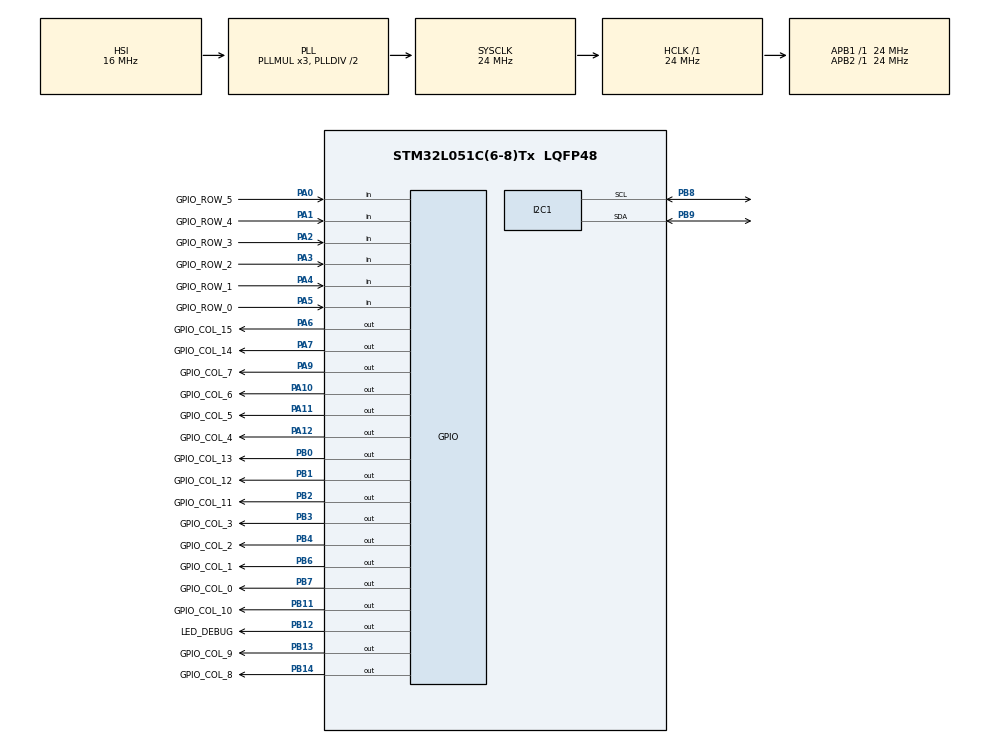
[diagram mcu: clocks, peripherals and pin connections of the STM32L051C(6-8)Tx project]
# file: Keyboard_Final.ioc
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I2C1.Timing=0x00506682
Mcu.Family=STM32L0
Mcu.Name=STM32L051C(6-8)Tx
Mcu.Package=LQFP48
PA0.GPIO_Label=GPIO_ROW_5
PA0.Signal=GPIO_Input
PA1.GPIO_Label=GPIO_ROW_4
PA1.Signal=GPIO_Input
PA10.GPIO_Label=GPIO_COL_6
PA10.Signal=GPIO_Output
PA11.GPIO_Label=GPIO_COL_5
PA11.Signal=GPIO_Output
PA12.GPIO_Label=GPIO_COL_4
PA12.Signal=GPIO_Output
PA13.Mode=Serial_Wire
PA13.Signal=SYS_SWDIO
PA14.Mode=Serial_Wire
PA14.Signal=SYS_SWCLK
PA2.GPIO_Label=GPIO_ROW_3
PA2.Signal=GPIO_Input
PA3.GPIO_Label=GPIO_ROW_2
PA3.Signal=GPIO_Input
PA4.GPIO_Label=GPIO_ROW_1
PA4.Signal=GPIO_Input
PA5.GPIO_Label=GPIO_ROW_0
PA5.Signal=GPIO_Input
PA6.GPIO_Label=GPIO_COL_15
PA6.Signal=GPIO_Output
PA7.GPIO_Label=GPIO_COL_14
PA7.Signal=GPIO_Output
PA9.GPIO_Label=GPIO_COL_7
PA9.Signal=GPIO_Output
PB0.GPIO_Label=GPIO_COL_13
PB0.Signal=GPIO_Output
PB1.GPIO_Label=GPIO_COL_12
PB1.Signal=GPIO_Output
PB11.GPIO_Label=GPIO_COL_10
PB11.Signal=GPIO_Output
PB12.GPIO_Label=LED_DEBUG
PB12.Signal=GPIO_Output
PB13.GPIO_Label=GPIO_COL_9
PB13.Signal=GPIO_Output
PB14.GPIO_Label=GPIO_COL_8
PB14.Signal=GPIO_Output
PB2.GPIO_Label=GPIO_COL_11
PB2.Signal=GPIO_Output
PB3.GPIO_Label=GPIO_COL_3
PB3.Signal=GPIO_Output
PB4.GPIO_Label=GPIO_COL_2
PB4.Signal=GPIO_Output
PB6.GPIO_Label=GPIO_COL_1
PB6.Signal=GPIO_Output
PB7.GPIO_Label=GPIO_COL_0
PB7.Signal=GPIO_Output
PB8.Mode=I2C
PB8.Signal=I2C1_SCL
PB9.Mode=I2C
PB9.Signal=I2C1_SDA
ProjectManager.HeapSize=0x200
ProjectManager.StackSize=0x400
ProjectManager.TargetToolchain=SW4STM32
RCC.AHBFreq_Value=24000000
RCC.APB1Freq_Value=24000000
RCC.APB1TimFreq_Value=24000000
RCC.APB2Freq_Value=24000000
RCC.APB2TimFreq_Value=24000000
RCC.HCLKFreq_Value=24000000
RCC.HSE_VALUE=8000000
RCC.HSI16_VALUE=16000000
RCC.HSI_VALUE=16000000
RCC.LSE_VALUE=32768
RCC.MSI_VALUE=2097000
RCC.SYSCLKFreq_VALUE=24000000
RCC.SYSCLKSource=RCC_SYSCLKSOURCE_PLLCLK
RCC.VCOOutputFreq_Value=48000000
board=custom

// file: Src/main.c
/* USER CODE BEGIN Header */
/**
  ******************************************************************************
  * @file           : main.c
  * @brief          : Main program body
  ******************************************************************************
  * @attention
  *
  * <h2><center>&copy; Copyright (c) 2019 STMicroelectronics.
  * All rights reserved.</center></h2>
  *
  * This software component is licensed by ST under BSD 3-Clause license,
  * the "License"; You may not use this file except in compliance with the
  * License. You may obtain a copy of the License at:
  *                        opensource.org/licenses/BSD-3-Clause
  *
  ******************************************************************************
  */
/* USER CODE END Header */

#include "main.h"
#include "keybd.h"
#include <stdlib.h>

/* USER CODE BEGIN PD */
#define ROWS	6
#define COLS	16
/* USER CODE END PD */

I2C_HandleTypeDef hi2c1;

void SystemClock_Config(void);
static void MX_GPIO_Init(void);
static void MX_I2C1_Init(void);

int main(void)
{
  /* USER CODE BEGIN 1 */

  // ALLOCATE MEMORY FOR STATE ARRAY
  int **state_array;
  state_array = malloc(ROWS * sizeof *state_array);
  for (int i = 0; i < ROWS; i++)
      state_array[i] = malloc(COLS * sizeof *state_array[i]);
  state_array_init(state_array, ROWS, COLS);

  /* USER CODE END 1 */

  /* MCU Configuration--------------------------------------------------------*/

  /* Reset of all peripherals, Initializes the Flash interface and the Systick. */
  HAL_Init();

  /* Configure the system clock */
  SystemClock_Config();

  /* Initialize all configured peripherals */
  MX_GPIO_Init();
  MX_I2C1_Init();

  /* Infinite loop */
  while (1)
  {
	matrixDebounce(state_array);
    /* USER CODE BEGIN 3 */
  }

  // FREE STATE ARRAY
  for (int i = 0; i < ROWS; i++)
      free(state_array[i]);
  free(state_array);

  /* USER CODE END 3 */
}

void SystemClock_Config(void)
{
  RCC_OscInitTypeDef RCC_OscInitStruct = {0};
  RCC_ClkInitTypeDef RCC_ClkInitStruct = {0};
  RCC_PeriphCLKInitTypeDef PeriphClkInit = {0};

  /** Configure the main internal regulator output voltage
  */
  __HAL_PWR_VOLTAGESCALING_CONFIG(PWR_REGULATOR_VOLTAGE_SCALE1);
  /** Initializes the CPU, AHB and APB busses clocks
  */
  RCC_OscInitStruct.OscillatorType = RCC_OSCILLATORTYPE_HSI;
  RCC_OscInitStruct.HSIState = RCC_HSI_ON;
  RCC_OscInitStruct.HSICalibrationValue = RCC_HSICALIBRATION_DEFAULT;
  RCC_OscInitStruct.PLL.PLLState = RCC_PLL_ON;
  RCC_OscInitStruct.PLL.PLLSource = RCC_PLLSOURCE_HSI;
  RCC_OscInitStruct.PLL.PLLMUL = RCC_PLLMUL_3;
  RCC_OscInitStruct.PLL.PLLDIV = RCC_PLLDIV_2;
  if (HAL_RCC_OscConfig(&RCC_OscInitStruct) != HAL_OK)
  {
    Error_Handler();
  }
  /** Initializes the CPU, AHB and APB busses clocks
  */
  RCC_ClkInitStruct.ClockType = RCC_CLOCKTYPE_HCLK|RCC_CLOCKTYPE_SYSCLK
                              |RCC_CLOCKTYPE_PCLK1|RCC_CLOCKTYPE_PCLK2;
  RCC_ClkInitStruct.SYSCLKSource = RCC_SYSCLKSOURCE_PLLCLK;
  RCC_ClkInitStruct.AHBCLKDivider = RCC_SYSCLK_DIV1;
  RCC_ClkInitStruct.APB1CLKDivider = RCC_HCLK_DIV1;
  RCC_ClkInitStruct.APB2CLKDivider = RCC_HCLK_DIV1;

  if (HAL_RCC_ClockConfig(&RCC_ClkInitStruct, FLASH_LATENCY_1) != HAL_OK)
  {
    Error_Handler();
  }
  PeriphClkInit.PeriphClockSelection = RCC_PERIPHCLK_I2C1;
  PeriphClkInit.I2c1ClockSelection = RCC_I2C1CLKSOURCE_PCLK1;
  if (HAL_RCCEx_PeriphCLKConfig(&PeriphClkInit) != HAL_OK)
  {
    Error_Handler();
  }
}

static void MX_I2C1_Init(void)
{

  hi2c1.Instance = I2C1;
  hi2c1.Init.Timing = 0x00506682;
  hi2c1.Init.OwnAddress1 = 0;
  hi2c1.Init.AddressingMode = I2C_ADDRESSINGMODE_7BIT;
  hi2c1.Init.DualAddressMode = I2C_DUALADDRESS_DISABLE;
  hi2c1.Init.OwnAddress2 = 0;
  hi2c1.Init.OwnAddress2Masks = I2C_OA2_NOMASK;
  hi2c1.Init.GeneralCallMode = I2C_GENERALCALL_DISABLE;
  hi2c1.Init.NoStretchMode = I2C_NOSTRETCH_DISABLE;
  if (HAL_I2C_Init(&hi2c1) != HAL_OK)
  {
    Error_Handler();
  }
  /** Configure Analogue filter
  */
  if (HAL_I2CEx_ConfigAnalogFilter(&hi2c1, I2C_ANALOGFILTER_ENABLE) != HAL_OK)
  {
    Error_Handler();
  }
  /** Configure Digital filter
  */
  if (HAL_I2CEx_ConfigDigitalFilter(&hi2c1, 0) != HAL_OK)
  {
    Error_Handler();
  }

}

static void MX_GPIO_Init(void)
{
  GPIO_InitTypeDef GPIO_InitStruct = {0};

  /* GPIO Ports Clock Enable */
  __HAL_RCC_GPIOA_CLK_ENABLE();
  __HAL_RCC_GPIOB_CLK_ENABLE();

  /*Configure GPIO pin Output Level */
  HAL_GPIO_WritePin(GPIOA, GPIO_COL_15_Pin|GPIO_COL_14_Pin|GPIO_COL_7_Pin|GPIO_COL_6_Pin
                          |GPIO_COL_5_Pin|GPIO_COL_4_Pin, GPIO_PIN_RESET);

  /*Configure GPIO pin Output Level */
  HAL_GPIO_WritePin(GPIOB, GPIO_COL_13_Pin|GPIO_COL_12_Pin|GPIO_COL_11_Pin|GPIO_COL_10_Pin
                          |LED_DEBUG_Pin|GPIO_COL_9_Pin|GPIO_COL_8_Pin|GPIO_COL_3_Pin
                          |GPIO_COL_2_Pin|GPIO_COL_1_Pin|GPIO_COL_0_Pin, GPIO_PIN_RESET);

  /*Configure GPIO pins : GPIO_ROW_5_Pin GPIO_ROW_4_Pin GPIO_ROW_3_Pin GPIO_ROW_2_Pin
                           GPIO_ROW_1_Pin GPIO_ROW_0_Pin */
  GPIO_InitStruct.Pin = GPIO_ROW_5_Pin|GPIO_ROW_4_Pin|GPIO_ROW_3_Pin|GPIO_ROW_2_Pin
                          |GPIO_ROW_1_Pin|GPIO_ROW_0_Pin;
  GPIO_InitStruct.Mode = GPIO_MODE_INPUT;
  GPIO_InitStruct.Pull = GPIO_NOPULL;
  HAL_GPIO_Init(GPIOA, &GPIO_InitStruct);

  /*Configure GPIO pins : GPIO_COL_15_Pin GPIO_COL_14_Pin GPIO_COL_7_Pin GPIO_COL_6_Pin
                           GPIO_COL_5_Pin GPIO_COL_4_Pin */
  GPIO_InitStruct.Pin = GPIO_COL_15_Pin|GPIO_COL_14_Pin|GPIO_COL_7_Pin|GPIO_COL_6_Pin
                          |GPIO_COL_5_Pin|GPIO_COL_4_Pin;
  GPIO_InitStruct.Mode = GPIO_MODE_OUTPUT_PP;
  GPIO_InitStruct.Pull = GPIO_NOPULL;
  GPIO_InitStruct.Speed = GPIO_SPEED_FREQ_LOW;
  HAL_GPIO_Init(GPIOA, &GPIO_InitStruct);

  /*Configure GPIO pins : GPIO_COL_13_Pin GPIO_COL_12_Pin GPIO_COL_11_Pin GPIO_COL_10_Pin
                           LED_DEBUG_Pin GPIO_COL_9_Pin GPIO_COL_8_Pin GPIO_COL_3_Pin
                           GPIO_COL_2_Pin GPIO_COL_1_Pin GPIO_COL_0_Pin */
  GPIO_InitStruct.Pin = GPIO_COL_13_Pin|GPIO_COL_12_Pin|GPIO_COL_11_Pin|GPIO_COL_10_Pin
                          |LED_DEBUG_Pin|GPIO_COL_9_Pin|GPIO_COL_8_Pin|GPIO_COL_3_Pin
                          |GPIO_COL_2_Pin|GPIO_COL_1_Pin|GPIO_COL_0_Pin;
  GPIO_InitStruct.Mode = GPIO_MODE_OUTPUT_PP;
  GPIO_InitStruct.Pull = GPIO_NOPULL;
  GPIO_InitStruct.Speed = GPIO_SPEED_FREQ_LOW;
  HAL_GPIO_Init(GPIOB, &GPIO_InitStruct);

}

void Error_Handler(void)
{
}

/************************ (C) COPYRIGHT STMicroelectronics *****END OF FILE****/
